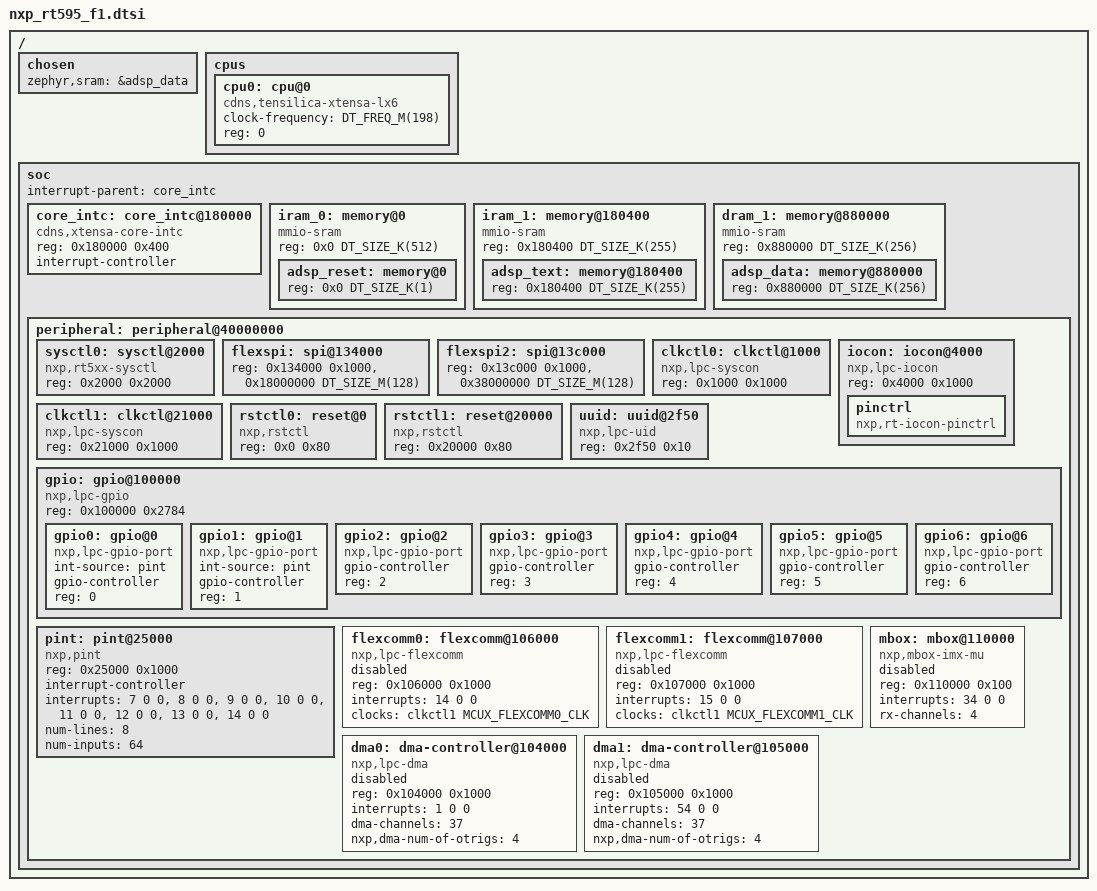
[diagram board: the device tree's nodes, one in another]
/*
 * Copyright 2025 NXP
 * SPDX-License-Identifier: Apache-2.0
 */

#include <xtensa/xtensa.dtsi>
#include <mem.h>
#include <freq.h>
#include <zephyr/dt-bindings/clock/mcux_lpc_syscon_clock.h>
#include <zephyr/dt-bindings/input/input-event-codes.h>

/ {
	chosen {
		zephyr,sram = &adsp_data;
	};

	cpus {
		#address-cells = <1>;
		#size-cells = <0>;

		cpu0: cpu@0 {
			device_type = "cpu";
			compatible = "cdns,tensilica-xtensa-lx6";
			clock-frequency = <DT_FREQ_M(198)>;
			reg = <0>;
		};
	};

	soc {
		interrupt-parent = <&core_intc>;

		/*
		 * Dummy interrupt controller node - IRQs are handled directly by platform code.
		 * INPUTMUX (IRQ allocation) is set up in mimxrt595s/fusionf1 soc.c.
		 */
		core_intc: core_intc@180000 {
			compatible = "cdns,xtensa-core-intc";
			reg = <0x180000 0x400>;
			interrupt-controller;
			#interrupt-cells = <3>;
		};

		iram_0: memory@0 {
			#address-cells = <1>;
			#size-cells = <1>;
			device_type = "memory";
			compatible = "mmio-sram";
			/* Reserve first 512kB of shared memory for ADSP. */
			reg = <0x0 DT_SIZE_K(512)>;

			/* Reset section must always be at 0 and at least 1kB. */
			adsp_reset: memory@0 {
				reg = <0x0 DT_SIZE_K(1)>;
			};
		};

		iram_1: memory@180400 {
			#address-cells = <1>;
			#size-cells = <1>;
			device_type = "memory";
			compatible = "mmio-sram";

			reg = <0x180400 DT_SIZE_K(255)>;
			/* Code and data sections can be moved around and resized if needed. */
			adsp_text: memory@180400 {
				reg = <0x180400 DT_SIZE_K(255)>;
			};
		};

		dram_1: memory@880000{
			#address-cells = <1>;
			#size-cells = <1>;
			device_type = "memory";
			compatible = "mmio-sram";

			reg = <0x880000 DT_SIZE_K(256)>;

			/* On RT595 ADSP shared RAM is mapped at offset 0 on the code bus and at
			 * offset 0x800000 on the data bus.
			 */
			adsp_data: memory@880000 {
				reg = <0x880000 DT_SIZE_K(256)>;
			};
		};

		peripheral: peripheral@40000000 {
			ranges = <0x0 0x40000000 0x10000000>;

			#address-cells = <1>;
			#size-cells = <1>;

			/*
			 * Dummy node - it does not instantiate a real driver, rather it provide the
			 * base address of the SYSCTL0 block for use with the "dsp" node.
			 */
			sysctl0: sysctl@2000 {
				reg = <0x2000 0x2000>;
				compatible = "nxp,rt5xx-sysctl";
			};
			/*
			 * Note that the offsets here are relative to the base address
			 * defined in either nxp_rt5xx_ns.dtsi or nxp_rt5xx.dtsi. The base
			 * addresses differ between non-secure (0x40000000) and secure
			 * modes (0x50000000).
			 */

			flexspi: spi@134000 {
				reg = <0x134000 0x1000>, <0x18000000 DT_SIZE_M(128)>;
			};

			flexspi2: spi@13c000 {
				reg = <0x13c000 0x1000>, <0x38000000 DT_SIZE_M(128)>;
			};

			clkctl0: clkctl@1000 {
				/* FIXME This chip does NOT have a syscon */
				compatible = "nxp,lpc-syscon";
				reg = <0x1000 0x1000>;
				#clock-cells = <1>;
			};

			iocon: iocon@4000 {
				compatible = "nxp,lpc-iocon";
				reg = <0x4000 0x1000>;

				pinctrl: pinctrl {
					compatible = "nxp,rt-iocon-pinctrl";
				};
			};

			clkctl1: clkctl@21000 {
				/* FIXME This chip does NOT have a syscon */
				compatible = "nxp,lpc-syscon";
				reg = <0x21000 0x1000>;
				#clock-cells = <1>;
			};

			rstctl0: reset@0 {
				compatible = "nxp,rstctl";
				reg = <0x0 0x80>;
				#reset-cells = <1>;
			};

			rstctl1: reset@20000 {
				compatible = "nxp,rstctl";
				reg = <0x20000 0x80>;
				#reset-cells = <1>;
			};

			uuid: uuid@2f50 {
				compatible = "nxp,lpc-uid";
				reg = <0x2f50 0x10>;
			};

			gpio: gpio@100000 {
				compatible = "nxp,lpc-gpio";
				reg = <0x100000 0x2784>;
				#address-cells = <1>;
				#size-cells = <0>;

				gpio0: gpio@0 {
					compatible = "nxp,lpc-gpio-port";
					int-source = "pint";
					gpio-controller;
					#gpio-cells = <2>;
					reg = <0>;
				};

				gpio1: gpio@1 {
					compatible = "nxp,lpc-gpio-port";
					int-source = "pint";
					gpio-controller;
					#gpio-cells = <2>;
					reg = <1>;
				};

				gpio2: gpio@2 {
					compatible = "nxp,lpc-gpio-port";
					gpio-controller;
					#gpio-cells = <2>;
					reg = <2>;
				};

				gpio3: gpio@3 {
					compatible = "nxp,lpc-gpio-port";
					gpio-controller;
					#gpio-cells = <2>;
					reg = <3>;
				};

				gpio4: gpio@4 {
					compatible = "nxp,lpc-gpio-port";
					gpio-controller;
					#gpio-cells = <2>;
					reg = <4>;
				};

				gpio5: gpio@5 {
					compatible = "nxp,lpc-gpio-port";
					gpio-controller;
					#gpio-cells = <2>;
					reg = <5>;
				};

				gpio6: gpio@6 {
					compatible = "nxp,lpc-gpio-port";
					gpio-controller;
					#gpio-cells = <2>;
					reg = <6>;
				};
			};

			pint: pint@25000 {
				compatible = "nxp,pint";
				reg = <0x25000 0x1000>;
				interrupt-controller;
				#interrupt-cells = <1>;
				#address-cells = <0>;
				interrupts = <7 0 0>, <8 0 0>, <9 0 0>, <10 0 0>,
					     <11 0 0>, <12 0 0>, <13 0 0>, <14 0 0>;
				num-lines = <8>;
				num-inputs = <64>;
			};

			flexcomm0: flexcomm@106000 {
				compatible = "nxp,lpc-flexcomm";
				reg = <0x106000 0x1000>;
				interrupts = <14 0 0>;
				clocks = <&clkctl1 MCUX_FLEXCOMM0_CLK>;
	//			resets = <&rstctl1 NXP_SYSCON_RESET(0, 8)>;
				status = "disabled";
			};

			flexcomm1: flexcomm@107000 {
				compatible = "nxp,lpc-flexcomm";
				reg = <0x107000 0x1000>;
				interrupts = <15 0 0>;
				clocks = <&clkctl1 MCUX_FLEXCOMM1_CLK>;
			//	resets = <&rstctl1 NXP_SYSCON_RESET(0, 9)>;
				status = "disabled";
			};


			dma0: dma-controller@104000 {
				compatible = "nxp,lpc-dma";
				reg = <0x104000 0x1000>;
				interrupts = <1 0 0>;
				dma-channels = <37>;
				nxp,dma-num-of-otrigs = <4>;
	//			nxp,dma-otrig-base-address = <RT595_DMA0_OTRIG_BASE>;
	//			nxp,dma-itrig-base-address = <RT595_DMA0_ITRIG_BASE>;
				status = "disabled";
				#dma-cells = <1>;
			};

			dma1: dma-controller@105000 {
				compatible = "nxp,lpc-dma";
				reg = <0x105000 0x1000>;
				interrupts = <54 0 0>;
				dma-channels = <37>;
				nxp,dma-num-of-otrigs = <4>;
	//			nxp,dma-otrig-base-address = <RT595_DMA1_OTRIG_BASE>;
	//			nxp,dma-itrig-base-address = <RT595_DMA1_ITRIG_BASE>;
				status = "disabled";
				#dma-cells = <1>;
			};


			mbox: mbox@110000 {
				compatible = "nxp,mbox-imx-mu";
				reg = <0x110000 0x100>;
				interrupts = <34 0 0>;
				rx-channels = <4>;
				#mbox-cells = <1>;
				status = "disabled";
			};

		};
	};
};
